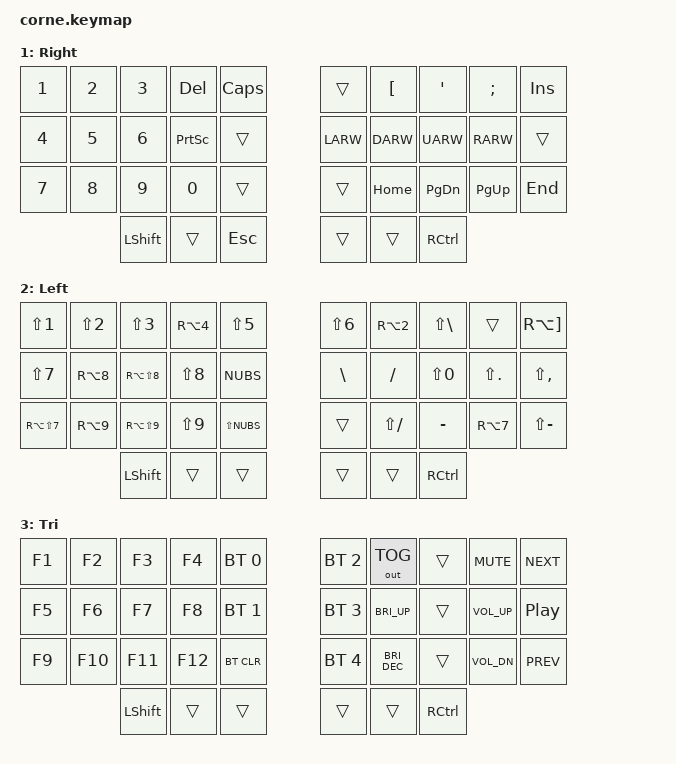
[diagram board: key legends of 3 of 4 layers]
 /*
 * Copyright (c) 2020 The ZMK Contributors
 *
 * SPDX-License-Identifier: MIT
 */

#include <behaviors.dtsi>
#include <dt-bindings/zmk/keys.h>
#include <dt-bindings/zmk/bt.h>
#include <dt-bindings/zmk/outputs.h>

// Home row mods macro
#define HRML(k2,k3,k4) &ht LALT k2  &ht LCTRL k3  &ht LGUI k4
#define HRMR(k1,k2,k3) &ht RGUI k1  &ht RCTRL k2  &ht RALT k3
#define WHRML(k2,k3,k4) &ht LALT k2  &ht LGUI k3  &ht LCTRL k4
#define WHRMR(k1,k2,k3) &ht RCTRL k1  &ht RGUI k2  &ht RALT k3

#define MAC 0
#define RIG 1
#define LEF 2
#define TRI 3

/ {
    chosen {
        zmk,physical-layout = &foostan_corne_5col_layout;
    };

    behaviors {
        ht: hold_tap {
            label = "hold_tap";
            compatible = "zmk,behavior-hold-tap";
            #binding-cells = <2>;
            flavor = "tap-preferred";
            tapping-term-ms = <220>;
            quick-tap-ms = <150>;
            global-quick-tap;
            bindings = <&kp>, <&kp>;
        };
    };

    conditional_layers {
        compatible = "zmk,conditional-layers";
        tri_layer {
            if-layers = <RIG LEF>;
            then-layer = <TRI>;
        };
    };

        keymap {
                compatible = "zmk,keymap";

            default_layer {
                display-name = "Base";
                bindings = <
            //╭──────────┬──────────┬──────────┬──────────┬──────────╮   ╭──────────┬──────────┬──────────┬──────────┬──────────╮
            //│  Q       │  W       │  E       │  R       │  T       │   │  Y       │  U       │  I       │  O       │  P       │
                &kp Q      HRML(W     , E        , R)      &kp T          &kp Y      HRMR( U     , I        , O)      &kp P
            //├──────────┼──────────┼──────────┼──────────┼──────────┤   ├──────────┼──────────┼──────────┼──────────┼──────────┤
            //│  A       │  S       │  D       │  F       │  G       │   │  H       │  J       │  K       │  L       │BACKSPACE │
                &kp A       &kp S      &kp D      &kp F     &kp G          &kp H      &kp J      &kp K      &kp L      &kp BSPC
            //├──────────┼──────────┼──────────┼──────────┼──────────┤   ├──────────┼──────────┼──────────┼──────────┼──────────┤
            //│  Z       │  X       │  C       │  V       │  B       │   │  N       │  M       │ ,        │ .        │ ENTER    │
                &kp Z      &kp X      &kp C      &kp V      &kp B          &kp N      &kp M      &kp COMMA  &kp DOT    &kp ENTER
            //╰──────────┴──────────┴──────────┼──────────┼──────────┤   ├──────────┼──────────┼──────────┴──────────┴──────────╯
                                      &kp LSHFT &lt LEF TAB  &kp ESC       &kp SPACE &lt RIG TAB &kp RCTRL
            //                      ╰──────────┴──────────┴──────────╯   ╰──────────┴──────────┴──────────╯
                >;
            };

            right_layer {
                display-name = "Right";
                bindings = <
            //╭──────────┬──────────┬──────────┬──────────┬──────────╮   ╭──────────┬──────────┬──────────┬──────────┬──────────╮
            //│ 1        │  2       │  3       │ DELETE   │ CapsLock │   │          │      Å   │        Ä │       Ö  │  INSERT  │
                &kp N1    &kp N2     &kp N3     &kp DEL     &kp CAPS          &trans   &kp LBKT    &kp SQT   &kp SEMI  &kp INS
            //├──────────┼──────────┼──────────┼──────────┼──────────┤   ├──────────┼──────────┼──────────┼──────────┼──────────┤
            //│ 4        │ 5        │ 6        │ PrintSc  │          |   |   LEFT   │ DOWN     │ UP       │ RIGHT    │          │
                &kp N4      &kp N5     &kp N6    &kp PSCRN   &trans        &kp LARW    &kp DARW   &kp UARW   &kp RARW   &trans 
            //├──────────┼──────────┼──────────┼──────────┼──────────┤   ├──────────┼──────────┼──────────┼──────────┼──────────┤
            //│ 7        │8         │    9     │     0    │          │   │          │ HOME     │ PAGE DN  │ PAGE UP  │ END      │
                &kp N7    &kp N8     &kp N9     &kp N0      &trans           &trans     &kp HOME   &kp PG_DN  &kp PG_UP  &kp END 
            //╰──────────┴──────────┴──────────┼──────────┼──────────┤   ├──────────┼──────────┼──────────┴──────────┴──────────╯
                                      &kp LSHFT     &trans     &kp ESC        &trans     &trans  &kp RCTRL
            //                      ╰──────────┴──────────┴──────────╯   ╰──────────┴──────────┴──────────╯
                >;
            };


            left_layer {
                display-name = "Left";
                bindings = <
            //╭──────────┬──────────┬──────────┬──────────┬──────────╮   ╭──────────┬──────────┬──────────┬──────────┬──────────╮
            //│  !       │  "       │  #       │  $       │  %       │   │    &     │  @       │  *       │          │  ~       │
               &kp LS(N1)  &kp LS(N2) &kp LS(N3) &kp RA(N4) &kp LS(N5)    &kp LS(N6)  &kp RA(N2) &kp LS(BSLH) &trans  &kp RA(RBKT)
            //├──────────┼──────────┼──────────┼──────────┼──────────┤   ├──────────┼──────────┼──────────┼──────────┼──────────┤
            //│  /       │  [       │  {       │  (       │     <    │   │   '      │  -       │  =       │     :    │  ;       │
            &kp LS(N7)    &kp RA(N8) &kp RA(LS(N8)) &kp LS(N8) &kp NUBS   &kp BSLH &kp FSLH    &kp LS(N0) &kp LS(DOT) &kp LS(COMMA)
            //├──────────┼──────────┼──────────┼──────────┼──────────┤   ├──────────┼──────────┼──────────┼──────────┼──────────┤
            //│  \       │  ]       │  }       │  )       │      >   │   │          │  _       │  +       │     │    │   ?      │
            &kp RA(LS(N7)) &kp RA(N9) &kp RA(LS(N9)) &kp LS(N9) &kp LS(NUBS) &trans &kp LS(FSLH) &kp MINUS  &kp RA(N7)  &kp LS(MINUS)
            //╰──────────┴──────────┴──────────┼──────────┼──────────┤   ├──────────┼──────────┼──────────┴──────────┴──────────╯
                                      &kp LSHFT     &trans     &trans         &trans     &trans  &kp RCTRL
            //                      ╰──────────┴──────────┴──────────╯   ╰──────────┴──────────┴──────────╯
                >;
            };
                                                                     
            tri_layer {
                display-name = "Tri";
                bindings = <
            //╭──────────┬──────────┬──────────┬───────────┬────────────╮   ╭────────────┬────────────┬──────────┬───────────┬──────────╮
            //│  F1      │  F2      │  F3      │  F4       │ PROFILE 0  │   │ PROFILE 2  │ TOGGLEOUT  │          │ VOL MUTE  │ NEXTSONG │
                &kp F1     &kp F2     &kp F3     &kp F4     &bt BT_SEL 0     &bt BT_SEL 2  &out OUT_TOG &trans    &kp C_MUTE  &kp C_NEXT
            //├──────────┼──────────┼──────────┼───────────┼────────────┤   ├────────────┼────────────┼──────────┼───────────┼──────────┤
            //│  F5      │  F6      │  F7      │  F8       │ PROFILE 1  │   │ PROFILE 3  │ INC BRIGHT │          │  VOL UP   │PAUSEMUSIC│
                &kp F5     &kp F6     &kp F7     &kp F8     &bt BT_SEL 1     &bt BT_SEL 3  &kp C_BRI_UP  &trans   &kp C_VOL_UP  &kp C_PP
            //├──────────┼──────────┼──────────┼───────────┼────────────┤   ├────────────┼────────────┼──────────┼───────────┼──────────┤
            //│  F9      │  F10     │  F11     │  F12      │  CLEAR BT  │   │ PROFILE 4  │ DEC BRIGHT │          |  VOL DOWN │ PREVSONG │
                &kp F9     &kp F10    &kp F11    &kp F12     &bt BT_CLR      &bt BT_SEL 4  &kp C_BRI_DEC  &trans   &kp C_VOL_DN &kp C_PREV
            //╰──────────┴──────────┴──────────┼───────────┼────────────┤   ├────────────┼────────────┼──────────┴───────────┴──────────╯
                                      &kp LSHFT     &trans     &trans         &trans     &trans  &kp RCTRL
            //                      ╰──────────┴──────────┴──────────╯   ╰──────────┴──────────┴──────────╯
                >;
            };
        };
};
